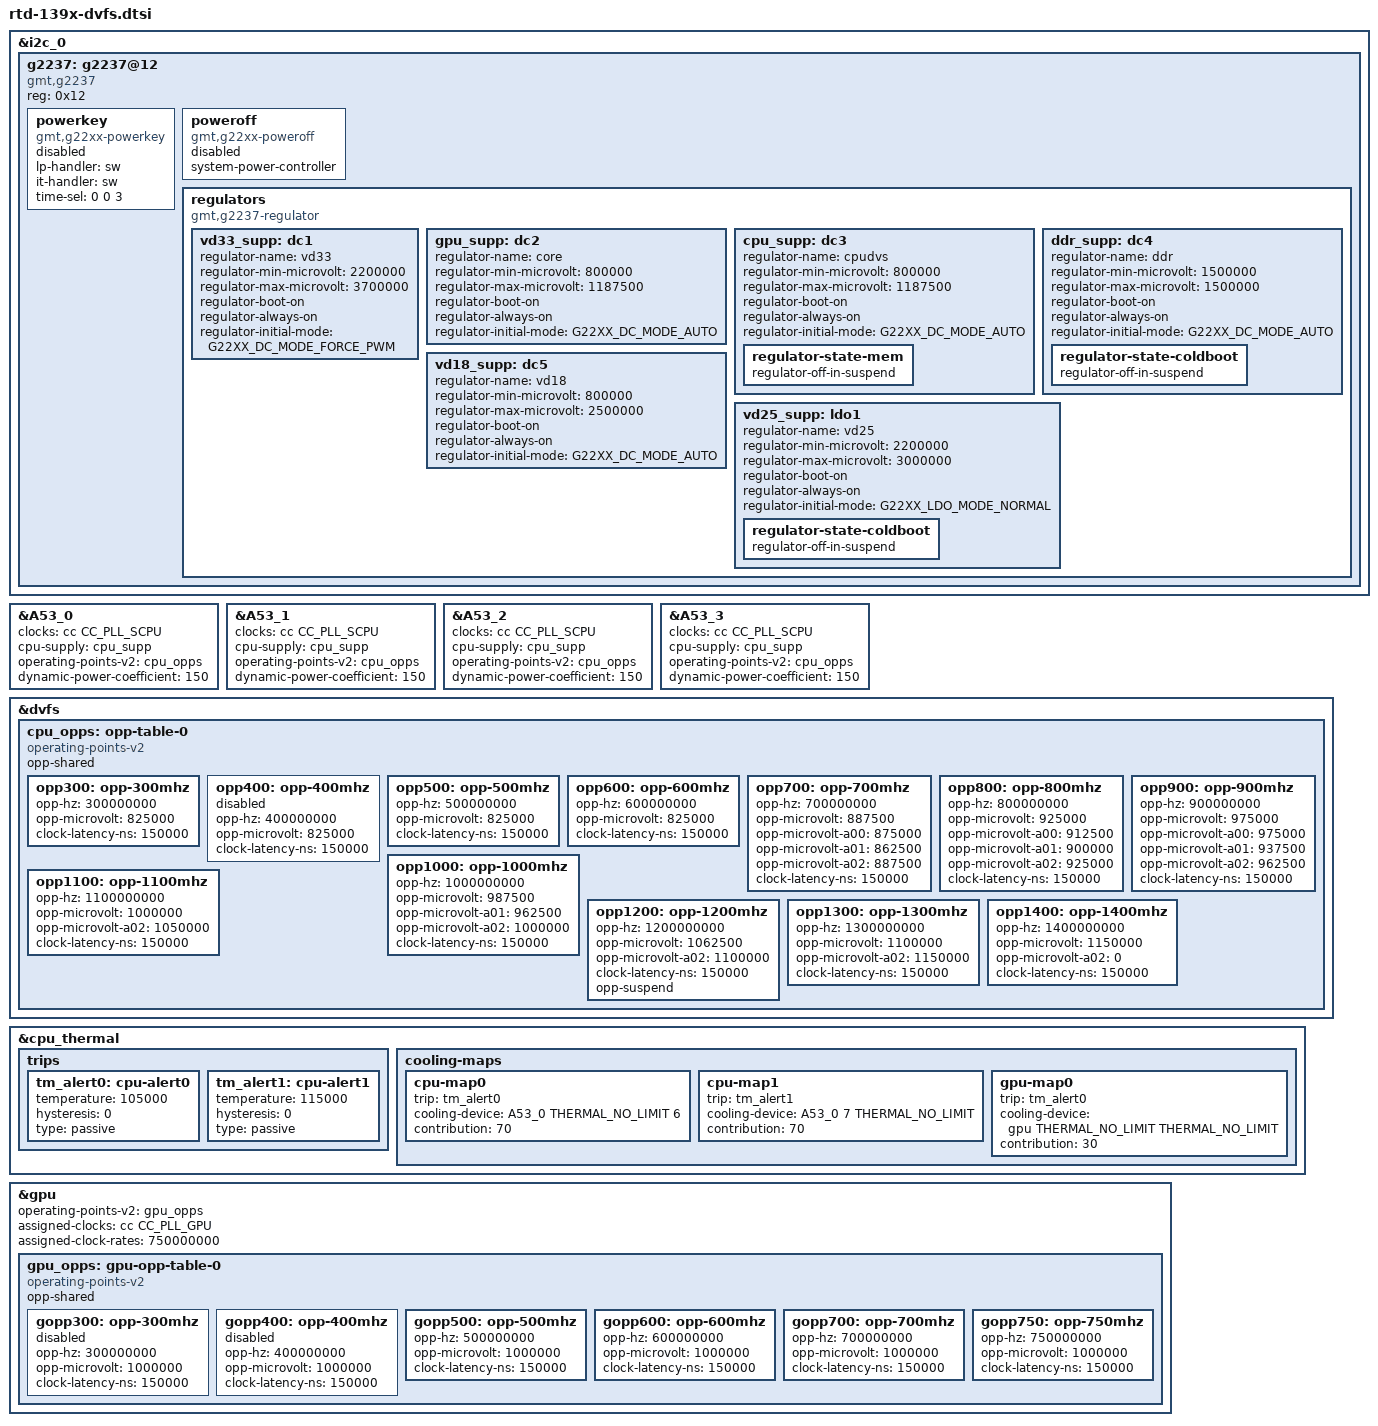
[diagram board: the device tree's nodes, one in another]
/*
 * RTD-139X DVFS with GMT G2237 PMIC
 */
#include <dt-bindings/regulator/gmt,g22xx.h>
#include <dt-bindings/thermal/thermal.h>

/* PMIC */
&i2c_0 {
	status = "okay";

	g2237: g2237@12 {
		compatible = "gmt,g2237";
		reg = <0x12>;
		status = "okay";
		powerkey: powerkey {
			compatible = "gmt,g22xx-powerkey";
			lp-handler = "sw";
			it-handler = "sw";
			time-sel = <0 0 3>;
			status = "disabled";
		};
		poweroff: poweroff {
			compatible = "gmt,g22xx-poweroff";
			system-power-controller;
			status = "disabled";
		};
		regulators: regulators {
			compatible = "gmt,g2237-regulator";
			status = "okay";
		};
	};
};

&g2237 {
	regulators {
		vd33_supp: dc1 {
			regulator-name = "vd33";
			regulator-min-microvolt = <2200000>;
			regulator-max-microvolt = <3700000>;

			regulator-boot-on;
			regulator-always-on;
			regulator-initial-mode = <G22XX_DC_MODE_FORCE_PWM>;

		};
		gpu_supp: dc2 {
			regulator-name = "core";
			regulator-min-microvolt = <800000>;
			regulator-max-microvolt = <1187500>;

			regulator-boot-on;
			regulator-always-on;
			regulator-initial-mode = <G22XX_DC_MODE_AUTO>;
		};
		cpu_supp: dc3 {
			regulator-name = "cpudvs";
			regulator-min-microvolt = <800000>;
			regulator-max-microvolt = <1187500>;

			regulator-boot-on;
			regulator-always-on;
			regulator-initial-mode = <G22XX_DC_MODE_AUTO>;
			regulator-state-mem {
				regulator-off-in-suspend;
			};
		};
		ddr_supp: dc4 {
			regulator-name = "ddr";
			regulator-min-microvolt = <1500000>;
			regulator-max-microvolt = <1500000>;
			regulator-boot-on;
			regulator-always-on;
			regulator-initial-mode = <G22XX_DC_MODE_AUTO>;
			regulator-state-coldboot {
				regulator-off-in-suspend;
			};

		};
		vd18_supp: dc5 {
			regulator-name = "vd18";
			regulator-min-microvolt = <800000>;
			regulator-max-microvolt = <2500000>;

			regulator-boot-on;
			regulator-always-on;
			regulator-initial-mode = <G22XX_DC_MODE_AUTO>;
		};
		vd25_supp: ldo1 {
			regulator-name = "vd25";
			regulator-min-microvolt = <2200000>;
			regulator-max-microvolt = <3000000>;

			regulator-boot-on;
			regulator-always-on;
			regulator-initial-mode = <G22XX_LDO_MODE_NORMAL>;
			regulator-state-coldboot {
				regulator-off-in-suspend;
			};
		};
	};
};

/* CPU nodes */
&A53_0 {
	clocks = <&cc CC_PLL_SCPU>;
	cpu-supply = <&cpu_supp>;
	operating-points-v2 = <&cpu_opps>;
	#cooling-cells = <2>;
	dynamic-power-coefficient = <150>;
};

&A53_1 {
	clocks = <&cc CC_PLL_SCPU>;
	cpu-supply = <&cpu_supp>;
	operating-points-v2 = <&cpu_opps>;
	#cooling-cells = <2>;
	dynamic-power-coefficient = <150>;
};

&A53_2 {
	clocks = <&cc CC_PLL_SCPU>;
	cpu-supply = <&cpu_supp>;
	operating-points-v2 = <&cpu_opps>;
	#cooling-cells = <2>;
	dynamic-power-coefficient = <150>;
};

&A53_3 {
	clocks = <&cc CC_PLL_SCPU>;
	cpu-supply = <&cpu_supp>;
	operating-points-v2 = <&cpu_opps>;
	#cooling-cells = <2>;
	dynamic-power-coefficient = <150>;
};

/* cpu opp table */
&dvfs {
	cpu_opps: opp-table-0 {
		compatible = "operating-points-v2";
		opp-shared;
		opp300: opp-300mhz {
			opp-hz = /bits/ 64 <300000000>;
			opp-microvolt = <825000>;
			clock-latency-ns = <150000>;
			status = "okay";
		};
		opp400: opp-400mhz {
			opp-hz = /bits/ 64 <400000000>;
			opp-microvolt = <825000>;
			clock-latency-ns = <150000>;
			status = "disabled";
		};
		opp500: opp-500mhz {
			opp-hz = /bits/ 64 <500000000>;
			opp-microvolt = <825000>;
			clock-latency-ns = <150000>;
			status = "okay";
		};
		opp600: opp-600mhz {
			opp-hz = /bits/ 64 <600000000>;
			opp-microvolt     = <825000>;
			clock-latency-ns = <150000>;
			status = "okay";
		};
		opp700: opp-700mhz {
			opp-hz = /bits/ 64 <700000000>;
			opp-microvolt     = <887500>;
			opp-microvolt-a00 = <875000>;
			opp-microvolt-a01 = <862500>;
			opp-microvolt-a02 = <887500>;
			clock-latency-ns = <150000>;
			status = "okay";
		};
		opp800: opp-800mhz {
			opp-hz = /bits/ 64 <800000000>;
			opp-microvolt     = <925000>;
			opp-microvolt-a00 = <912500>;
			opp-microvolt-a01 = <900000>;
			opp-microvolt-a02 = <925000>;
			clock-latency-ns = <150000>;
			status = "okay";
		};
		opp900: opp-900mhz {
			opp-hz = /bits/ 64 <900000000>;
			opp-microvolt     = <975000>;
			opp-microvolt-a00 = <975000>;
			opp-microvolt-a01 = <937500>;
			opp-microvolt-a02 = <962500>;
			clock-latency-ns = <150000>;
			status = "okay";
		};
		opp1000: opp-1000mhz {
			opp-hz = /bits/ 64 <1000000000>;
			opp-microvolt     = <987500>;
			opp-microvolt-a01 = <962500>;
			opp-microvolt-a02 = <1000000>;
			clock-latency-ns = <150000>;
			status = "okay";
		};
		opp1100: opp-1100mhz {
			opp-hz = /bits/ 64 <1100000000>;
			opp-microvolt     = <1000000>;
			opp-microvolt-a02 = <1050000>;
			clock-latency-ns = <150000>;
			status = "okay";
		};
		opp1200: opp-1200mhz {
			opp-hz = /bits/ 64 <1200000000>;
			opp-microvolt     = <1062500>;
			opp-microvolt-a02 = <1100000>;
			clock-latency-ns = <150000>;
			opp-suspend;
			status = "okay";
		};
		opp1300: opp-1300mhz {
			opp-hz = /bits/ 64 <1300000000>;
			opp-microvolt     = <1100000>;
			opp-microvolt-a02 = <1150000>;
			clock-latency-ns = <150000>;
			status = "okay";
		};
		opp1400: opp-1400mhz {
			opp-hz = /bits/ 64 <1400000000>;
			opp-microvolt     = <1150000>;
			opp-microvolt-a02 = <0>;
			clock-latency-ns = <150000>;
			status = "okay";
		};
	};
};

/*
 * thermal_zone
 */
&cpu_thermal {
	trips {
		tm_alert0: cpu-alert0 {
			temperature = <105000>;
			hysteresis = <0>;
			type = "passive";
		};
		tm_alert1: cpu-alert1 {
			temperature = <115000>;
			hysteresis = <0>;
			type = "passive";
		};
	};
	cooling-maps {
		cpu-map0 {
			trip = <&tm_alert0>;
			cooling-device = <&A53_0 THERMAL_NO_LIMIT 6>;
			contribution = <70>;
		};
		cpu-map1 {
			trip = <&tm_alert1>;
			cooling-device = <&A53_0 7 THERMAL_NO_LIMIT>;
			contribution = <70>;
		};
		gpu-map0 {
			trip = <&tm_alert0>;
			cooling-device = <&gpu THERMAL_NO_LIMIT THERMAL_NO_LIMIT>;
			contribution = <30>;
		};
	};
};

&gpu {
	#cooling-cells = <2>;
	operating-points-v2 = <&gpu_opps>;
	assigned-clocks =      <&cc CC_PLL_GPU>;
	assigned-clock-rates = <750000000>;

	gpu_opps: gpu-opp-table-0 {
		compatible = "operating-points-v2";
		opp-shared;
		gopp300: opp-300mhz {
			opp-hz = /bits/ 64 <300000000>;
			opp-microvolt = <1000000>;
			clock-latency-ns = <150000>;
			status = "disabled";
		};
		gopp400: opp-400mhz {
			opp-hz = /bits/ 64 <400000000>;
			opp-microvolt = <1000000>;
			clock-latency-ns = <150000>;
			status = "disabled";
		};
		gopp500: opp-500mhz {
			opp-hz = /bits/ 64 <500000000>;
			opp-microvolt = <1000000>;
			clock-latency-ns = <150000>;
			status = "okay";
		};
		gopp600: opp-600mhz {
			opp-hz = /bits/ 64 <600000000>;
			opp-microvolt = <1000000>;
			clock-latency-ns = <150000>;
			status = "okay";
		};
		gopp700: opp-700mhz {
			opp-hz = /bits/ 64 <700000000>;
			opp-microvolt = <1000000>;
			clock-latency-ns = <150000>;
			status = "okay";
		};
		gopp750: opp-750mhz {
			opp-hz = /bits/ 64 <750000000>;
			opp-microvolt = <1000000>;
			clock-latency-ns = <150000>;
			status = "okay";
		};
	};
};
